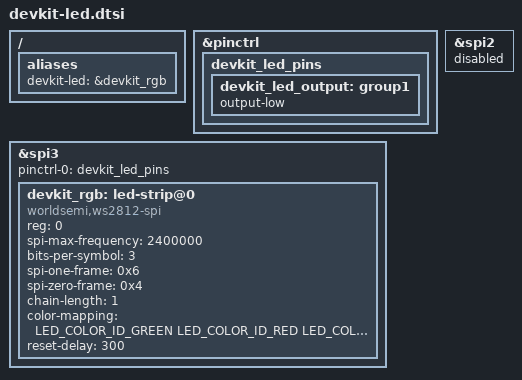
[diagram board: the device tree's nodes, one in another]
#include <zephyr/dt-bindings/led/led.h>

/ {
	aliases {
		devkit-led = &devkit_rgb;
	};
};

&pinctrl {
	devkit_led_pins: devkit_led_pins {
		devkit_led_output: group1 {
			output-low;
		};
	};
};

/* The isolated bench test only routes the selected LED data pin. */
&spi2 {
	status = "disabled";
};

&spi3 {
	status = "okay";
	pinctrl-0 = <&devkit_led_pins>;
	pinctrl-names = "default";

	devkit_rgb: led-strip@0 {
		compatible = "worldsemi,ws2812-spi";
		reg = <0>;
		spi-max-frequency = <2400000>;
		bits-per-symbol = <3>;
		spi-one-frame = <0x6>;
		spi-zero-frame = <0x4>;
		chain-length = <1>;
		color-mapping = <LED_COLOR_ID_GREEN LED_COLOR_ID_RED LED_COLOR_ID_BLUE>;
		reset-delay = <300>;
	};
};
